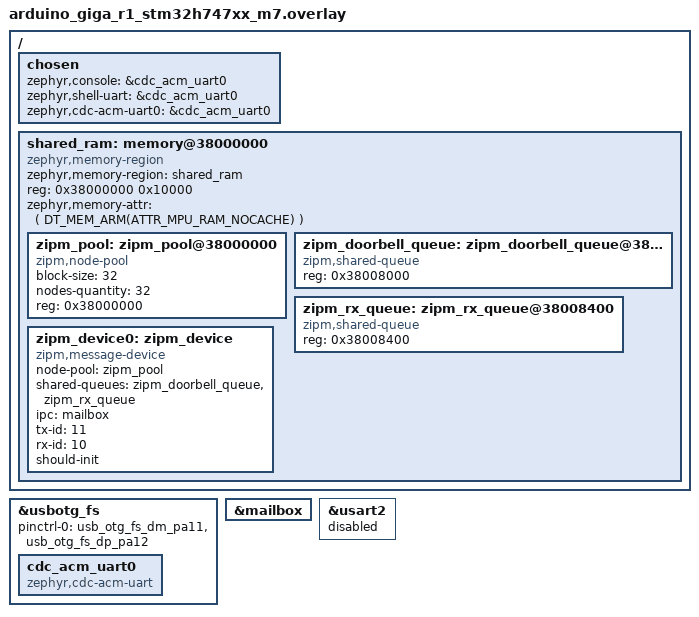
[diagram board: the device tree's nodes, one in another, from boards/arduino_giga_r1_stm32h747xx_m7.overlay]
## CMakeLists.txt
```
# SPDX-License-Identifier: Apache-2.0

cmake_minimum_required(VERSION 3.20.0)

find_package(Zephyr REQUIRED HINTS $ENV{ZEPHYR_BASE})
project(zipm_tx)

target_sources(app PRIVATE src/main.c)

# Temporary solution for esp32 variants until its AMP gets fixed on zephyr tree:
zephyr_sources_ifdef(CONFIG_BOARD_ESP32S3_DEVKITM_ESP32S3_PROCPU src/zephyr.c)
```

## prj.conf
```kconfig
CONFIG_ZIPM=y
CONFIG_MBOX=y
CONFIG_SYSTEM_WORKQUEUE_STACK_SIZE=4096
```

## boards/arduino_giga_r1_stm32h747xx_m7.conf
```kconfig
CONFIG_USB_DEVICE_INITIALIZE_AT_BOOT=y
CONFIG_SHELL=y
CONFIG_PRINTK=y
CONFIG_LOG=y
CONFIG_USB_DEVICE_STACK=y
CONFIG_USB_WORKQUEUE_STACK_SIZE=16384
CONFIG_USB_DEVICE_PRODUCT="ZIPM-Arduino-TX"
CONFIG_USB_DEVICE_PID=0x0004
CONFIG_MAIN_STACK_SIZE=8912
CONFIG_SERIAL=y
CONFIG_CONSOLE=y
CONFIG_UART_CONSOLE=y
CONFIG_UART_LINE_CTRL=y
CONFIG_MBOX_STM32_HSEM=y
```

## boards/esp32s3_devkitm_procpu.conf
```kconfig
CONFIG_IPM=n
CONFIG_SHELL=y
CONFIG_PRINTK=y
CONFIG_LOG=y
```

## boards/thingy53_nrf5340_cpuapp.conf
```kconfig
CONFIG_SOC_NRF53_CPUNET_ENABLE=y

CONFIG_USB_DEVICE_INITIALIZE_AT_BOOT=y
CONFIG_SHELL=y
CONFIG_PRINTK=y
CONFIG_LOG=y
CONFIG_USB_DEVICE_STACK=y
CONFIG_USB_WORKQUEUE_STACK_SIZE=16384
CONFIG_USB_DEVICE_PRODUCT="ZIPM-Thingy-TX"
CONFIG_USB_DEVICE_PID=0x0004
CONFIG_MAIN_STACK_SIZE=8912
CONFIG_SERIAL=y
CONFIG_CONSOLE=y
CONFIG_UART_CONSOLE=y
CONFIG_UART_LINE_CTRL=y
```

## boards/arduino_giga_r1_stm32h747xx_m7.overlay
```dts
/*
 * Copyright (c) 2024 Felipe Neves
 *
 * SPDX-License-Identifier: Apache-2.0
 */

/ {
	chosen {
		zephyr,console = &cdc_acm_uart0;
		zephyr,shell-uart = &cdc_acm_uart0;
		zephyr,cdc-acm-uart0 = &cdc_acm_uart0;
	};

	/* We redefine the memory and remove the cache attr due to cache coherence issues */
	/delete-node/ memory@38000000;

	shared_ram: memory@38000000 {
			zephyr,memory-region = "shared_ram";
			compatible = "zephyr,memory-region", "mmio-sram";
			reg = <0x38000000 0x10000>;
			zephyr,memory-attr = <( DT_MEM_ARM(ATTR_MPU_RAM_NOCACHE) )>;
	};
	
};

zephyr_udc0: &usbotg_fs {
	pinctrl-0 = <&usb_otg_fs_dm_pa11 &usb_otg_fs_dp_pa12>;
	pinctrl-names = "default";
	status = "okay";

	cdc_acm_uart0: cdc_acm_uart0 {
		compatible = "zephyr,cdc-acm-uart";
	};
};

&cdc_acm_uart0 {
	status = "okay";
};

&shared_ram {
	#address-cells = <1>;
	#size-cells = <0>;
  
	zipm_pool: zipm_pool@38000000 {
		compatible = "zipm,node-pool";
		block-size = <32>;
		nodes-quantity = <32>;
		reg = <0x38000000>;
	};

	zipm_doorbell_queue: zipm_doorbell_queue@38008000 {
		compatible = "zipm,shared-queue";
		reg = <0x38008000>;
	};
  
	zipm_rx_queue: zipm_rx_queue@38008400 {
		compatible = "zipm,shared-queue";
		reg = <0x38008400>;
	};

	zipm_device0: zipm_device {
        compatible = "zipm,message-device";
        status = "okay";
        node-pool = <&zipm_pool>;
        shared-queues = <&zipm_doorbell_queue &zipm_rx_queue>;
        ipc = <&mailbox>;
		tx-id = <11>;
		rx-id = <10>;
		should-init;
    };
};

&mailbox {
	status = "okay";
};

&usart2 {
	status = "disabled";
};
```

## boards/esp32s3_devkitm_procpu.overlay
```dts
/*
 * Copyright (c) 2024 Felipe Neves
 *
 * SPDX-License-Identifier: Apache-2.0
 */

/ {
	aliases {
		led0 = &red_led_0;
	};

	leds {
		compatible = "gpio-leds";
		red_led_0: led_0 {
			gpios = <&gpio0 7 GPIO_ACTIVE_HIGH>;
			label = "User LD0";
		};
	};
};

&shm0 {
	#address-cells = <1>;
	#size-cells = <0>;

	zipm_pool: zipm_pool@3fcbd400 {
		compatible = "zipm,node-pool";
		block-size = <32>;
		nodes-quantity = <32>;
		reg = <0x3fcbd400>;
	};

	zipm_doorbell_queue: zipm_doorbell_queue@3fcbd800 {
		compatible = "zipm,shared-queue";
		reg = <0x3fcbd800>;
	};

	zipm_rx_queue: zipm_rx_queue@3fcbdc00 {
		compatible = "zipm,shared-queue";
		reg = <0x3fcbdc00>;
	};

	zipm_device0: zipm_device {
        compatible = "zipm,message-device";
        status = "okay";
        node-pool = <&zipm_pool>;
        shared-queues = <&zipm_doorbell_queue &zipm_rx_queue>;
        ipc = <&mbox0>;
		tx-id = <1>;
		rx-id = <0>;
		should-init;
    };
};

&mbox0 {
	status = "okay";
};
```

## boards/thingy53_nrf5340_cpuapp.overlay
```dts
/*
 * Copyright (c) 2024 Felipe Neves
 *
 * SPDX-License-Identifier: Apache-2.0
 */

/* Use the bottom 32KB of the shared RAM */
&sram0_shared {
	#address-cells = <1>;
	#size-cells = <0>;
  
	zipm_pool: zipm_pool@20078000 {
		compatible = "zipm,node-pool";
		block-size = <32>;
		nodes-quantity = <32>;
		reg = <0x20078000>;
	};

	zipm_doorbell_queue: zipm_doorbell_queue@2007C000 {
		compatible = "zipm,shared-queue";
		reg = <0x2007C000>;
	};
  
	zipm_rx_queue: zipm_rx_queue@2007C400 {
		compatible = "zipm,shared-queue";
		reg = <0x2007C400>;
	};

	zipm_device0: zipm_device {
        compatible = "zipm,message-device";
        status = "okay";
        node-pool = <&zipm_pool>;
        shared-queues = <&zipm_doorbell_queue &zipm_rx_queue>;
        ipc = <&mbox>;
		tx-id = <0>;
		rx-id = <1>;
		should-init;
    };
};
```

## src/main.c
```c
/*
 * Copyright (c) 2024 Felipe Neves
 *
 * SPDX-License-Identifier: Apache-2.0
 */

#include <stdio.h>
#include <zephyr/kernel.h>
#include <zephyr/drivers/gpio.h>
#include <zephyr/drivers/uart.h>
#include <zephyr/usb/usb_device.h>
#include <zipm/zipm.h>

static const struct gpio_dt_spec led = GPIO_DT_SPEC_GET(DT_ALIAS(led0), gpios);
static const struct device *handle = DEVICE_DT_GET(DT_NODELABEL(zipm_device0));
static struct zipm_callback callback;
static char rx_msg[64] = {0};
static char tx_msg[] = {"Say something secondary core! \0"};

static int rx_queue = 1;
static int doorbell_queue = 0;

static void zipm_event_callback(const struct device *dev, int sq, void *user_data)
{
	int copied = 0;
	size_t block_size;
	int ret;

	if(sq == rx_queue) {
		gpio_pin_toggle_dt(&led);
		do {
			ret = zipm_receive(handle, &rx_msg[copied], &block_size, rx_queue);
			if(ret > 0) {
				copied += block_size;
			}
		}while(ret != 0);
		printk("%lld: Other core said: %s \n", k_uptime_get(), (const char *)rx_msg);
	}
}

int main(void)
{
	zipm_register_event_callback(handle, &callback, zipm_event_callback, NULL);

	if (!gpio_is_ready_dt(&led)) {
		return 0;
	}

	gpio_pin_configure_dt(&led, GPIO_OUTPUT_ACTIVE);

	while(1) {
		k_msleep(500);
		zipm_send(handle, &tx_msg, sizeof(tx_msg), doorbell_queue, 0);
	}

	return 0;
}
```
